# CY8C5888LTQ_LP097 register map
File version: 0.1
Registers are 8-bit, read-write, no defined reset value unless marked. A register's access mark holds for its fields unless they carry their own. Offsets are from the block's base; [hi:lo] are bit positions; 'fields as' and 'values as' point back to an identical list.

## UART_LOG — UART
Base 0x00000000
0x4000642F RX_UART_LOG_RX_ADDRESS1 — RX Address1 Register
0x4000643F RX_UART_LOG_RX_ADDRESS2 — RX Address2 Register
0x4000644C TX_UART_LOG_TX_DATA — TX Data Register
0x4000644F RX_UART_LOG_RX_DATA — RX Data Register
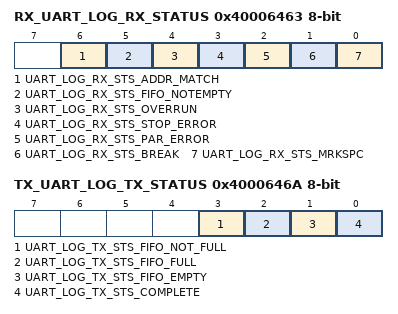
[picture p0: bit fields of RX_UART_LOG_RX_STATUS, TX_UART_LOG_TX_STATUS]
0x40006463 RX_UART_LOG_RX_STATUS — RX status register
  [6] UART_LOG_RX_STS_ADDR_MATCH ro, [5] UART_LOG_RX_STS_FIFO_NOTEMPTY ro, [4] UART_LOG_RX_STS_OVERRUN ro, [3] UART_LOG_RX_STS_STOP_ERROR ro, [2] UART_LOG_RX_STS_PAR_ERROR ro, [1] UART_LOG_RX_STS_BREAK ro, [0] UART_LOG_RX_STS_MRKSPC ro
0x4000646A TX_UART_LOG_TX_STATUS — TX status register
  [3] UART_LOG_TX_STS_FIFO_NOT_FULL ro, [2] UART_LOG_TX_STS_FIFO_FULL ro, [1] UART_LOG_TX_STS_FIFO_EMPTY ro, [0] UART_LOG_TX_STS_COMPLETE ro

## UART_Zigbee — UART
Base 0x00000000
0x40006426 RX_UART_Zigbee_RX_ADDRESS1 — RX Address1 Register
0x40006436 RX_UART_Zigbee_RX_ADDRESS2 — RX Address2 Register
0x40006446 RX_UART_Zigbee_RX_DATA — RX Data Register
0x4000644D TX_UART_Zigbee_TX_DATA — TX Data Register
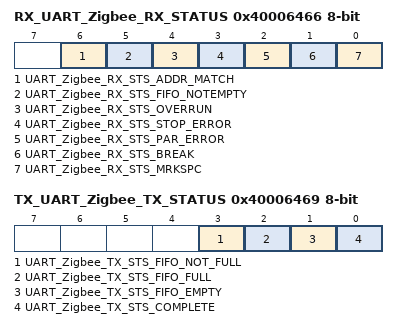
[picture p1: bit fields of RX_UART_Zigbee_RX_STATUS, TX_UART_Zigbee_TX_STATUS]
0x40006466 RX_UART_Zigbee_RX_STATUS — RX status register
  [6] UART_Zigbee_RX_STS_ADDR_MATCH ro, [5] UART_Zigbee_RX_STS_FIFO_NOTEMPTY ro, [4] UART_Zigbee_RX_STS_OVERRUN ro, [3] UART_Zigbee_RX_STS_STOP_ERROR ro, [2] UART_Zigbee_RX_STS_PAR_ERROR ro, [1] UART_Zigbee_RX_STS_BREAK ro, [0] UART_Zigbee_RX_STS_MRKSPC ro
0x40006469 TX_UART_Zigbee_TX_STATUS — TX status register
  [3] UART_Zigbee_TX_STS_FIFO_NOT_FULL ro, [2] UART_Zigbee_TX_STS_FIFO_FULL ro, [1] UART_Zigbee_TX_STS_FIFO_EMPTY ro, [0] UART_Zigbee_TX_STS_COMPLETE ro

## Engine_Direction_FR
Base 0x00000000
0x40006576 Engine_Direction_FR_CONTROL_REG

## PWM_Front
Base 0x00000000
0x4000642A PWM_Front_COMPARE_1 16-bit — UDB.D0 - Assigned Compare1 Value
0x4000643A PWM_Front_COMPARE_2 16-bit — UDB.D1 - Assigned Compare2 Value
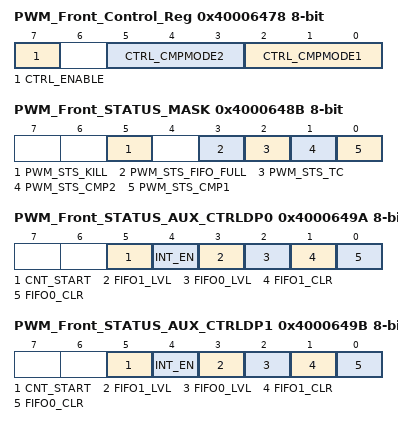
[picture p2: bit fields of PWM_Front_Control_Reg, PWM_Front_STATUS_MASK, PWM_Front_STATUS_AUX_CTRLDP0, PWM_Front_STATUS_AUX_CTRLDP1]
0x40006478 PWM_Front_Control_Reg — UDB Control Register - Assigned Control Register Value
  [7] CTRL_ENABLE — Enable the PWM
  [5:3] CTRL_CMPMODE2 — Compare mode 2
  [2:0] CTRL_CMPMODE1 — Compare mode 1
0x4000648B PWM_Front_STATUS_MASK — UDB Status bits Interrupt Mask Enable Register
  [5] PWM_STS_KILL ro — Enables the Interrupt on Kill
  [3] PWM_STS_FIFO_FULL ro — FIFO Full Status Mask
  [2] PWM_STS_TC ro — Enables the Interrupt on Terminal Count
  [1] PWM_STS_CMP2 ro — Enables the Interrupt on Compare 2
  [0] PWM_STS_CMP1 ro — Enables the Interrupt on Compare 1
0x4000649A PWM_Front_STATUS_AUX_CTRLDP0 — UDB Auxilliary Control Register
  [5] CNT_START — FIFO0 clear
    0=E_CNT_START0 (Disable counter); 1=E_CNT_START1 (Enable counter)
  [4] INT_EN
    0=E_INT_EN0 (Interrupt disabled); 1=E_INT_EN1 (Interrupt enabled)
  [3] FIFO1_LVL — FIFO level
    0=E_FIFO_LVL_0 (FIFO LVL: input mode: FIFO not full; output mode: FIFO not empty); 1=E_FIFO_LVL_1 (FIFO LVL: input mode: FIFO at least 1/2 empty; output mode: FIFO at least 1/2 full)
  [2] FIFO0_LVL — FIFO level
    values as FIFO1_LVL
  [1] FIFO1_CLR — FIFO1 clear
    0=E_FIFO_CLR_0 (Normal FIFO operation); 1=E_FIFO_CLR_1 (Clear FIFO state)
  [0] FIFO0_CLR — FIFO0 clear
    values as FIFO1_CLR
0x4000649B PWM_Front_STATUS_AUX_CTRLDP1 — UDB Auxilliary Control Register
  fields as PWM_Front_STATUS_AUX_CTRLDP0

## Engine_Direction_RL
Base 0x00000000
0x40006574 Engine_Direction_RL_CONTROL_REG

## PWM_Rear
Base 0x00000000
0x40006525 PWM_Rear_COMPARE_1 16-bit — UDB.D0 - Assigned Compare1 Value
0x40006535 PWM_Rear_COMPARE_2 16-bit — UDB.D1 - Assigned Compare2 Value
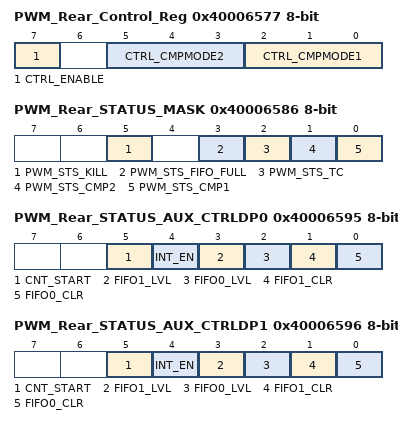
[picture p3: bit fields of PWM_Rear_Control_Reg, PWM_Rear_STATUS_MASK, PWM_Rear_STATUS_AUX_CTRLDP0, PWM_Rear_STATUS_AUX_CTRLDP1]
0x40006577 PWM_Rear_Control_Reg — UDB Control Register - Assigned Control Register Value
  [7] CTRL_ENABLE — Enable the PWM
  [5:3] CTRL_CMPMODE2 — Compare mode 2
  [2:0] CTRL_CMPMODE1 — Compare mode 1
0x40006586 PWM_Rear_STATUS_MASK — UDB Status bits Interrupt Mask Enable Register
  [5] PWM_STS_KILL ro — Enables the Interrupt on Kill
  [3] PWM_STS_FIFO_FULL ro — FIFO Full Status Mask
  [2] PWM_STS_TC ro — Enables the Interrupt on Terminal Count
  [1] PWM_STS_CMP2 ro — Enables the Interrupt on Compare 2
  [0] PWM_STS_CMP1 ro — Enables the Interrupt on Compare 1
0x40006595 PWM_Rear_STATUS_AUX_CTRLDP0 — UDB Auxilliary Control Register
  [5] CNT_START — FIFO0 clear
    0=E_CNT_START0 (Disable counter); 1=E_CNT_START1 (Enable counter)
  [4] INT_EN
    0=E_INT_EN0 (Interrupt disabled); 1=E_INT_EN1 (Interrupt enabled)
  [3] FIFO1_LVL — FIFO level
    0=E_FIFO_LVL_0 (FIFO LVL: input mode: FIFO not full; output mode: FIFO not empty); 1=E_FIFO_LVL_1 (FIFO LVL: input mode: FIFO at least 1/2 empty; output mode: FIFO at least 1/2 full)
  [2] FIFO0_LVL — FIFO level
    values as FIFO1_LVL
  [1] FIFO1_CLR — FIFO1 clear
    0=E_FIFO_CLR_0 (Normal FIFO operation); 1=E_FIFO_CLR_1 (Clear FIFO state)
  [0] FIFO0_CLR — FIFO0 clear
    values as FIFO1_CLR
0x40006596 PWM_Rear_STATUS_AUX_CTRLDP1 — UDB Auxilliary Control Register
  fields as PWM_Rear_STATUS_AUX_CTRLDP0
